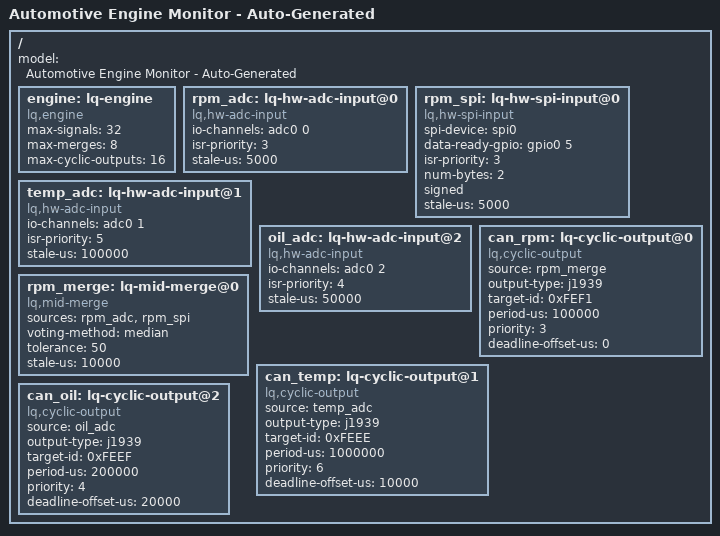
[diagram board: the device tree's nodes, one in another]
/dts-v1/;

/ {
    model = "Automotive Engine Monitor - Auto-Generated";
    
    /* ========================================================================
     * ENGINE: Root configuration
     * ======================================================================== */
    
    engine: lq-engine {
        compatible = "lq,engine";
        max-signals = <32>;
        max-merges = <8>;
        max-cyclic-outputs = <16>;
    };
    
    /* ========================================================================
     * HARDWARE INPUTS: ISR handlers will be auto-generated
     * ======================================================================== */
    
    /* ADC input: Primary RPM sensor */
    rpm_adc: lq-hw-adc-input@0 {
        compatible = "lq,hw-adc-input";
        status = "okay";
        
        io-channels = <&adc0 0>;      /* ADC0 channel 0 */
        isr-priority = <3>;
        stale-us = <5000>;            /* 5ms */
    };
    
    /* SPI input: Secondary RPM sensor */
    rpm_spi: lq-hw-spi-input@0 {
        compatible = "lq,hw-spi-input";
        status = "okay";
        
        spi-device = <&spi0>;
        data-ready-gpio = <&gpio0 5 0>;
        isr-priority = <3>;
        num-bytes = <2>;
        signed;
        stale-us = <5000>;
    };
    
    /* ADC input: Engine temperature */
    temp_adc: lq-hw-adc-input@1 {
        compatible = "lq,hw-adc-input";
        status = "okay";
        
        io-channels = <&adc0 1>;      /* ADC0 channel 1 */
        isr-priority = <5>;
        stale-us = <100000>;          /* 100ms */
    };
    
    /* ADC input: Oil pressure */
    oil_adc: lq-hw-adc-input@2 {
        compatible = "lq,hw-adc-input";
        status = "okay";
        
        io-channels = <&adc0 2>;      /* ADC0 channel 2 */
        isr-priority = <4>;
        stale-us = <50000>;           /* 50ms */
    };
    
    /* ========================================================================
     * MID-LEVEL PROCESSING: Merge and validation
     * ======================================================================== */
    
    /* Merge dual RPM sensors */
    rpm_merge: lq-mid-merge@0 {
        compatible = "lq,mid-merge";
        status = "okay";
        
        sources = <&rpm_adc &rpm_spi>;
        voting-method = "median";
        tolerance = <50>;             /* Max 50 RPM spread */
        stale-us = <10000>;
    };
    
    /* ========================================================================
     * CYCLIC OUTPUTS: Auto-generate deadline scheduling
     * ======================================================================== */
    
    /* CAN output: Engine RPM at 10Hz */
    can_rpm: lq-cyclic-output@0 {
        compatible = "lq,cyclic-output";
        status = "okay";
        
        source = <&rpm_merge>;
        output-type = "j1939";
        target-id = <0xFEF1>;         /* J1939 Engine Speed PGN */
        period-us = <100000>;         /* 100ms = 10Hz */
        priority = <3>;
        deadline-offset-us = <0>;
    };
    
    /* CAN output: Engine temperature at 1Hz */
    can_temp: lq-cyclic-output@1 {
        compatible = "lq,cyclic-output";
        status = "okay";
        
        source = <&temp_adc>;
        output-type = "j1939";
        target-id = <0xFEEE>;         /* J1939 Engine Temperature PGN */
        period-us = <1000000>;        /* 1s = 1Hz */
        priority = <6>;
        deadline-offset-us = <10000>; /* Stagger by 10ms */
    };
    
    /* CAN output: Oil pressure at 5Hz */
    can_oil: lq-cyclic-output@2 {
        compatible = "lq,cyclic-output";
        status = "okay";
        
        source = <&oil_adc>;
        output-type = "j1939";
        target-id = <0xFEEF>;         /* J1939 Engine Fluid Level/Pressure PGN */
        period-us = <200000>;         /* 200ms = 5Hz */
        priority = <4>;
        deadline-offset-us = <20000>; /* Stagger by 20ms */
    };
};
